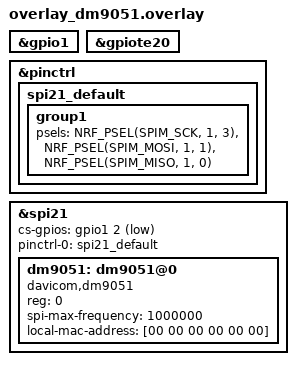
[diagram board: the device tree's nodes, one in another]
/* SPI 腳位在 gpio1，必須啟用 gpiote20 */
&gpio1 {
	status = "okay";
};

&gpiote20 {
	status = "okay";
};

/* 中斷腳位在 gpio0，必須啟用 gpiote30 */
/*&gpio0 {
	status = "okay";
};
&gpiote30 {
	status = "okay";
};*/

/* 重置腳位在 gpio2，無需 GPIOTE（僅輸出控制）*/
/*&gpio2 {
	status = "okay";
};*/

&pinctrl {
	spi21_default: spi21_default {
		group1 {
			psels = <NRF_PSEL(SPIM_SCK, 1, 3)>,
				<NRF_PSEL(SPIM_MOSI, 1, 1)>,
				<NRF_PSEL(SPIM_MISO, 1, 0)>;
		};
	};

	/*spi21_sleep: spi21_sleep {
		group1 {
			psels = <NRF_PSEL(SPIM_SCK, 1, 3)>,
				<NRF_PSEL(SPIM_MOSI, 1, 1)>,
				<NRF_PSEL(SPIM_MISO, 1, 0)>;
			low-power-enable;
		};
	};*/
};

&spi21 {
	status = "okay";
	/*clocks = <&hfpll>;*/
	cs-gpios = <&gpio1 2 GPIO_ACTIVE_LOW>;  /* CS on P1.2 */
	pinctrl-0 = <&spi21_default>;
	/*pinctrl-1 = <&spi21_sleep>;*/
	pinctrl-names = "default";
	
	dm9051: dm9051@0 {
		compatible = "davicom,dm9051";
		reg = <0>;
		spi-max-frequency = <1000000>;  /* 1MHz - minimum for debugging */
		/* INT 腳位 */
		/* int-gpios = <&gpio0 3 GPIO_ACTIVE_LOW>; */
		/* Reset 腳位 */
		/* reset-gpios = <&gpio2 0 GPIO_ACTIVE_LOW>; */
		local-mac-address = [00 00 00 00 00 00]; /* [00 11 22 33 44 55]; */
	};
};
